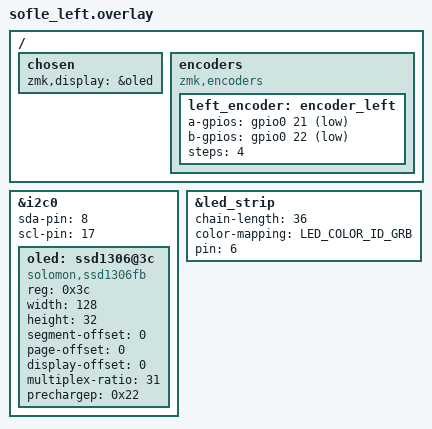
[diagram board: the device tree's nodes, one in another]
/ {
    chosen {
        zmk,display = &oled;
    };

    encoders {
        compatible = "zmk,encoders";

        left_encoder: encoder_left {
            a-gpios = <&gpio0 21 (GPIO_PULL_UP | GPIO_ACTIVE_LOW)>;
            b-gpios = <&gpio0 22 (GPIO_PULL_UP | GPIO_ACTIVE_LOW)>;
            steps = <4>;
        };
    };
};

&i2c0 {
    status = "okay";
    sda-pin = <8>;
    scl-pin = <17>;

    oled: ssd1306@3c {
        compatible = "solomon,ssd1306fb";
        reg = <0x3c>;
        width = <128>;
        height = <32>;
        segment-offset = <0>;
        page-offset = <0>;
        display-offset = <0>;
        multiplex-ratio = <31>;
        prechargep = <0x22>;
    };
};

&led_strip {
    status = "okay";
    chain-length = <36>;
    color-mapping = <LED_COLOR_ID_GRB>;
    pin = <6>;
};
